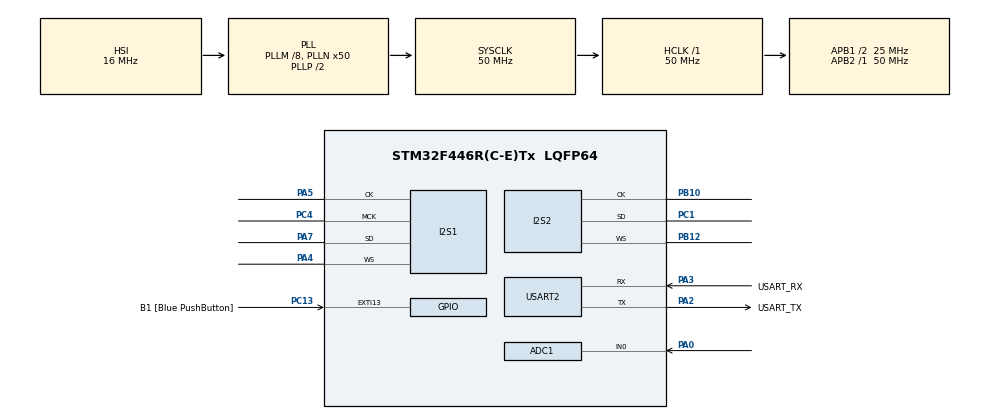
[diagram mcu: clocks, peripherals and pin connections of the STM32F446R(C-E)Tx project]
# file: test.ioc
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Mcu.Family=STM32F4
PH0-OSC_IN.Signal=RCC_OSC_IN
RCC.CortexFreq_Value=50000000
I2S1.ErrorAudioFreq=1.72 %
PB10.Mode=Half_Duplex_Master
ADC1.ContinuousConvMode=DISABLE
PA14.GPIO_Label=TCK
Dma.SPI2_TX.1.PeriphInc=DMA_PINC_DISABLE
I2S1.Mode=I2S_MODE_MASTER_RX
PC13.GPIO_Label=B1 [Blue PushButton]
NVIC.DMA1_Stream4_IRQn=true\:0\:0\:false\:false\:true\:false\:true
I2S1.Instance=SPI$Index
RCC.SYSCLKSource=RCC_SYSCLKSOURCE_PLLCLK
ProjectManager.StackSize=0x400
Dma.SPI1_RX.0.Direction=DMA_PERIPH_TO_MEMORY
PA4.Mode=Half_Duplex_Master
I2S1.DataFormat=I2S_DATAFORMAT_24B
RCC.HCLKFreq_Value=50000000
ADC1.Resolution=ADC_RESOLUTION_10B
RCC.APB2TimFreq_Value=50000000
NVIC.DMA2_Stream0_IRQn=true\:0\:0\:false\:false\:true\:false\:true
RCC.AHBFreq_Value=50000000
PH0-OSC_IN.Mode=HSE-External-Oscillator
ADC1.Channel-0\#ChannelRegularConversion=ADC_CHANNEL_0
RCC.HSE_VALUE=8000000
Dma.SPI1_RX.0.PeriphInc=DMA_PINC_DISABLE
PC14-OSC32_IN.Mode=LSE-External-Oscillator
PA14.Mode=Serial_Wire
SH.ADCx_IN0.0=ADC1_IN0,IN0
I2S2.DataFormat=I2S_DATAFORMAT_24B
ADC1.SamplingTime-0\#ChannelRegularConversion=ADC_SAMPLETIME_3CYCLES
RCC.FLatency-AdvancedSettings=FLASH_LATENCY_1
Dma.SPI2_TX.1.FIFOMode=DMA_FIFOMODE_DISABLE
PH1-OSC_OUT.Mode=HSE-External-Oscillator
Mcu.Package=LQFP64
PB12.Mode=Half_Duplex_Master
Dma.SPI2_TX.1.Mode=DMA_CIRCULAR
USART2.VirtualMode=VM_ASYNC
PA2.GPIO_Label=USART_TX
Dma.SPI2_TX.1.Instance=DMA1_Stream4
Dma.Request1=SPI2_TX
RCC.APB1TimFreq_Value=50000000
Dma.Request0=SPI1_RX
PC4.Mode=Master_Clock_Activated
PA3.Signal=USART2_RX
PA5.Mode=Half_Duplex_Master
PB3.GPIO_Label=SWO
PC15-OSC32_OUT.Mode=LSE-External-Oscillator
Dma.SPI2_TX.1.MemInc=DMA_MINC_ENABLE
I2S2.AudioFreq=I2S_AUDIOFREQ_48K
ADC1.Rank-0\#ChannelRegularConversion=1
PA7.Mode=Half_Duplex_Master
I2S2.Instance=SPI$Index
PC13.Signal=GPXTI13
PC4.Signal=I2S1_MCK
I2S1.AudioFreq=I2S_AUDIOFREQ_48K
Dma.SPI1_RX.0.Mode=DMA_CIRCULAR
RCC.APB1CLKDivider=RCC_HCLK_DIV2
PC14-OSC32_IN.Signal=RCC_OSC32_IN
PA0-WKUP.Signal=ADCx_IN0
Dma.SPI1_RX.0.FIFOMode=DMA_FIFOMODE_DISABLE
PA13.Signal=SYS_JTMS-SWDIO
PA3.Mode=Asynchronous
ProjectManager.TargetToolchain=STM32CubeIDE
I2S1.VirtualMode=I2S_MODE_MASTER
I2S2.VirtualMode=I2S_MODE_MASTER
RCC.USBFreq_Value=50000000
PC15-OSC32_OUT.Signal=RCC_OSC32_OUT
PB10.Signal=I2S2_CK
PA5.Signal=I2S1_CK
board=NUCLEO-F446RE
Dma.SPI2_TX.1.Direction=DMA_MEMORY_TO_PERIPH
RCC.VCOOutputFreq_Value=100000000
RCC.APB2Freq_Value=50000000
Dma.SPI2_TX.1.PeriphDataAlignment=DMA_PDATAALIGN_WORD
Dma.SPI2_TX.1.Priority=DMA_PRIORITY_LOW
Dma.SPI1_RX.0.Instance=DMA2_Stream0
Dma.SPI1_RX.0.PeriphDataAlignment=DMA_PDATAALIGN_WORD
PH1-OSC_OUT.Signal=RCC_OSC_OUT
Dma.SPI1_RX.0.MemDataAlignment=DMA_MDATAALIGN_WORD
I2S1.FullDuplexMode=I2S_FULLDUPLEXMODE_DISABLE
PA13.Mode=Serial_Wire
Mcu.Name=STM32F446R(C-E)Tx
Dma.SPI1_RX.0.MemInc=DMA_MINC_ENABLE
PA2.Signal=USART2_TX
PA13.GPIO_Label=TMS
I2S2.FullDuplexMode=I2S_FULLDUPLEXMODE_DISABLE
RCC.48MHZClocksFreq_Value=84000000
PB3.Signal=SYS_JTDO-SWO
PA4.Signal=I2S1_WS
RCC.SYSCLKFreq_VALUE=50000000
ADC1.master=1
I2S2.ErrorAudioFreq=1.72 %
PC13.GPIO_ModeDefaultEXTI=GPIO_MODE_IT_FALLING
PA14.Signal=SYS_JTCK-SWCLK
ProjectManager.HeapSize=0x200
Dma.SPI1_RX.0.Priority=DMA_PRIORITY_LOW
RCC.HSI_VALUE=16000000
NVIC.PriorityGroup=NVIC_PRIORITYGROUP_0
ADC1.NbrOfConversionFlag=1
RCC.PLLM=8
RCC.PLLN=50
PA2.Mode=Asynchronous
I2S1.RealAudioFreq=48.828 KHz
RCC.APB1Freq_Value=25000000
I2S2.RealAudioFreq=48.828 KHz
Dma.SPI2_TX.1.MemDataAlignment=DMA_MDATAALIGN_WORD
RCC.PLLI2SN=50
PC1.Signal=I2S2_SD
PB12.Signal=I2S2_WS
PC1.Mode=Half_Duplex_Master
PA3.GPIO_Label=USART_RX
RCC.PLLI2SM=8
PA7.Signal=I2S1_SD

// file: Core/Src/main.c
/* USER CODE BEGIN Header */
/**
  ******************************************************************************
  * @file           : main.c
  * @brief          : Main program body
  ******************************************************************************
  * @attention
  *
  * <h2><center>&copy; Copyright (c) 2021 STMicroelectronics.
  * All rights reserved.</center></h2>
  *
  * This software component is licensed by ST under BSD 3-Clause license,
  * the "License"; You may not use this file except in compliance with the
  * License. You may obtain a copy of the License at:
  *                        opensource.org/licenses/BSD-3-Clause
  *
  ******************************************************************************
  */
/* USER CODE END Header */
#include "main.h"

ADC_HandleTypeDef hadc1;

I2S_HandleTypeDef hi2s1;
I2S_HandleTypeDef hi2s2;
DMA_HandleTypeDef hdma_spi1_rx;
DMA_HandleTypeDef hdma_spi2_tx;

UART_HandleTypeDef huart2;

void SystemClock_Config(void);
static void MX_GPIO_Init(void);
static void MX_DMA_Init(void);
static void MX_USART2_UART_Init(void);
static void MX_I2S1_Init(void);
static void MX_I2S2_Init(void);
static void MX_ADC1_Init(void);
/* USER CODE BEGIN PFP */
uint16_t rxBuf[8];
uint16_t txBuf[8];
//volatile int v=1;
/* USER CODE END PFP */

int main(void)
{

  /* MCU Configuration--------------------------------------------------------*/

  /* Reset of all peripherals, Initializes the Flash interface and the Systick. */
  HAL_Init();

  /* Configure the system clock */
  SystemClock_Config();

  /* Initialize all configured peripherals */
  MX_GPIO_Init();
  MX_DMA_Init();
  MX_USART2_UART_Init();
  MX_I2S1_Init();
  MX_I2S2_Init();
  MX_ADC1_Init();
  HAL_I2S_Receive_DMA(&hi2s1, rxBuf, 4);
  HAL_I2S_Transmit_DMA(&hi2s2, txBuf, 4);

  /* Infinite loop */
  while (1)
  {

  }
}
void HAL_I2S_RxHalfCpltCallback(I2S_HandleTypeDef *hi2s1)
{
	  int left=(rxBuf[0]<<16 | rxBuf[1]);
	  int right=(rxBuf[2]<<16 | rxBuf[3]);
	  txBuf[0]=(left>>16)&0xFFFF;
	  txBuf[1]=left&0xFFFF;
	  txBuf[2]=(right>>16)&0xFFFF;
	  txBuf[3]=right&0xFFFF;
}
void HAL_I2S_RxCpltCallback(I2S_HandleTypeDef *hi2s1)
{
	  int left=(rxBuf[4]<<16 | rxBuf[5]);
	  int right=(rxBuf[6]<<16 | rxBuf[7]);
	  txBuf[4]=(left>>16)&0xFFFF;
	  txBuf[5]=left&0xFFFF;
	  txBuf[6]=(right>>16)&0xFFFF;
	  txBuf[7]=right&0xFFFF;
}
void SystemClock_Config(void)
{
  RCC_OscInitTypeDef RCC_OscInitStruct = {0};
  RCC_ClkInitTypeDef RCC_ClkInitStruct = {0};
  RCC_PeriphCLKInitTypeDef PeriphClkInitStruct = {0};

  /** Configure the main internal regulator output voltage
  */
  __HAL_RCC_PWR_CLK_ENABLE();
  __HAL_PWR_VOLTAGESCALING_CONFIG(PWR_REGULATOR_VOLTAGE_SCALE3);
  /** Initializes the RCC Oscillators according to the specified parameters
  * in the RCC_OscInitTypeDef structure.
  */
  RCC_OscInitStruct.OscillatorType = RCC_OSCILLATORTYPE_HSI;
  RCC_OscInitStruct.HSIState = RCC_HSI_ON;
  RCC_OscInitStruct.HSICalibrationValue = RCC_HSICALIBRATION_DEFAULT;
  RCC_OscInitStruct.PLL.PLLState = RCC_PLL_ON;
  RCC_OscInitStruct.PLL.PLLSource = RCC_PLLSOURCE_HSI;
  RCC_OscInitStruct.PLL.PLLM = 8;
  RCC_OscInitStruct.PLL.PLLN = 50;
  RCC_OscInitStruct.PLL.PLLP = RCC_PLLP_DIV2;
  RCC_OscInitStruct.PLL.PLLQ = 2;
  RCC_OscInitStruct.PLL.PLLR = 2;
  if (HAL_RCC_OscConfig(&RCC_OscInitStruct) != HAL_OK)
  {
    Error_Handler();
  }
  /** Initializes the CPU, AHB and APB buses clocks
  */
  RCC_ClkInitStruct.ClockType = RCC_CLOCKTYPE_HCLK|RCC_CLOCKTYPE_SYSCLK
                              |RCC_CLOCKTYPE_PCLK1|RCC_CLOCKTYPE_PCLK2;
  RCC_ClkInitStruct.SYSCLKSource = RCC_SYSCLKSOURCE_PLLCLK;
  RCC_ClkInitStruct.AHBCLKDivider = RCC_SYSCLK_DIV1;
  RCC_ClkInitStruct.APB1CLKDivider = RCC_HCLK_DIV2;
  RCC_ClkInitStruct.APB2CLKDivider = RCC_HCLK_DIV1;

  if (HAL_RCC_ClockConfig(&RCC_ClkInitStruct, FLASH_LATENCY_1) != HAL_OK)
  {
    Error_Handler();
  }
  PeriphClkInitStruct.PeriphClockSelection = RCC_PERIPHCLK_I2S_APB1|RCC_PERIPHCLK_I2S_APB2;
  PeriphClkInitStruct.PLLI2S.PLLI2SN = 50;
  PeriphClkInitStruct.PLLI2S.PLLI2SP = RCC_PLLI2SP_DIV2;
  PeriphClkInitStruct.PLLI2S.PLLI2SM = 8;
  PeriphClkInitStruct.PLLI2S.PLLI2SR = 2;
  PeriphClkInitStruct.PLLI2S.PLLI2SQ = 2;
  PeriphClkInitStruct.PLLI2SDivQ = 1;
  PeriphClkInitStruct.I2sApb2ClockSelection = RCC_I2SAPB2CLKSOURCE_PLLI2S;
  PeriphClkInitStruct.I2sApb1ClockSelection = RCC_I2SAPB1CLKSOURCE_PLLI2S;
  if (HAL_RCCEx_PeriphCLKConfig(&PeriphClkInitStruct) != HAL_OK)
  {
    Error_Handler();
  }
}

static void MX_ADC1_Init(void)
{

  ADC_ChannelConfTypeDef sConfig = {0};

  /** Configure the global features of the ADC (Clock, Resolution, Data Alignment and number of conversion)
  */
  hadc1.Instance = ADC1;
  hadc1.Init.ClockPrescaler = ADC_CLOCK_SYNC_PCLK_DIV2;
  hadc1.Init.Resolution = ADC_RESOLUTION_10B;
  hadc1.Init.ScanConvMode = DISABLE;
  hadc1.Init.ContinuousConvMode = DISABLE;
  hadc1.Init.DiscontinuousConvMode = DISABLE;
  hadc1.Init.ExternalTrigConvEdge = ADC_EXTERNALTRIGCONVEDGE_NONE;
  hadc1.Init.ExternalTrigConv = ADC_SOFTWARE_START;
  hadc1.Init.DataAlign = ADC_DATAALIGN_RIGHT;
  hadc1.Init.NbrOfConversion = 1;
  hadc1.Init.DMAContinuousRequests = DISABLE;
  hadc1.Init.EOCSelection = ADC_EOC_SINGLE_CONV;
  if (HAL_ADC_Init(&hadc1) != HAL_OK)
  {
    Error_Handler();
  }
  /** Configure for the selected ADC regular channel its corresponding rank in the sequencer and its sample time.
  */
  sConfig.Channel = ADC_CHANNEL_0;
  sConfig.Rank = 1;
  sConfig.SamplingTime = ADC_SAMPLETIME_3CYCLES;
  if (HAL_ADC_ConfigChannel(&hadc1, &sConfig) != HAL_OK)
  {
    Error_Handler();
  }

}

static void MX_I2S1_Init(void)
{

  hi2s1.Instance = SPI1;
  hi2s1.Init.Mode = I2S_MODE_MASTER_RX;
  hi2s1.Init.Standard = I2S_STANDARD_PHILIPS;
  hi2s1.Init.DataFormat = I2S_DATAFORMAT_24B;
  hi2s1.Init.MCLKOutput = I2S_MCLKOUTPUT_ENABLE;
  hi2s1.Init.AudioFreq = I2S_AUDIOFREQ_48K;
  hi2s1.Init.CPOL = I2S_CPOL_LOW;
  hi2s1.Init.ClockSource = I2S_CLOCK_PLL;
  hi2s1.Init.FullDuplexMode = I2S_FULLDUPLEXMODE_DISABLE;
  if (HAL_I2S_Init(&hi2s1) != HAL_OK)
  {
    Error_Handler();
  }

}

static void MX_I2S2_Init(void)
{

  hi2s2.Instance = SPI2;
  hi2s2.Init.Mode = I2S_MODE_MASTER_TX;
  hi2s2.Init.Standard = I2S_STANDARD_PHILIPS;
  hi2s2.Init.DataFormat = I2S_DATAFORMAT_24B;
  hi2s2.Init.MCLKOutput = I2S_MCLKOUTPUT_DISABLE;
  hi2s2.Init.AudioFreq = I2S_AUDIOFREQ_48K;
  hi2s2.Init.CPOL = I2S_CPOL_LOW;
  hi2s2.Init.ClockSource = I2S_CLOCK_PLL;
  hi2s2.Init.FullDuplexMode = I2S_FULLDUPLEXMODE_DISABLE;
  if (HAL_I2S_Init(&hi2s2) != HAL_OK)
  {
    Error_Handler();
  }

}

static void MX_USART2_UART_Init(void)
{

  huart2.Instance = USART2;
  huart2.Init.BaudRate = 115200;
  huart2.Init.WordLength = UART_WORDLENGTH_8B;
  huart2.Init.StopBits = UART_STOPBITS_1;
  huart2.Init.Parity = UART_PARITY_NONE;
  huart2.Init.Mode = UART_MODE_TX_RX;
  huart2.Init.HwFlowCtl = UART_HWCONTROL_NONE;
  huart2.Init.OverSampling = UART_OVERSAMPLING_16;
  if (HAL_UART_Init(&huart2) != HAL_OK)
  {
    Error_Handler();
  }

}

static void MX_DMA_Init(void)
{

  /* DMA controller clock enable */
  __HAL_RCC_DMA2_CLK_ENABLE();
  __HAL_RCC_DMA1_CLK_ENABLE();

  /* DMA interrupt init */
  /* DMA1_Stream4_IRQn interrupt configuration */
  HAL_NVIC_SetPriority(DMA1_Stream4_IRQn, 0, 0);
  HAL_NVIC_EnableIRQ(DMA1_Stream4_IRQn);
  /* DMA2_Stream0_IRQn interrupt configuration */
  HAL_NVIC_SetPriority(DMA2_Stream0_IRQn, 0, 0);
  HAL_NVIC_EnableIRQ(DMA2_Stream0_IRQn);

}

static void MX_GPIO_Init(void)
{
  GPIO_InitTypeDef GPIO_InitStruct = {0};

  /* GPIO Ports Clock Enable */
  __HAL_RCC_GPIOC_CLK_ENABLE();
  __HAL_RCC_GPIOH_CLK_ENABLE();
  __HAL_RCC_GPIOA_CLK_ENABLE();
  __HAL_RCC_GPIOB_CLK_ENABLE();

  /*Configure GPIO pin : B1_Pin */
  GPIO_InitStruct.Pin = B1_Pin;
  GPIO_InitStruct.Mode = GPIO_MODE_IT_FALLING;
  GPIO_InitStruct.Pull = GPIO_NOPULL;
  HAL_GPIO_Init(B1_GPIO_Port, &GPIO_InitStruct);

}

void Error_Handler(void)
{
  __disable_irq();
  while (1)
  {
  }
}

/************************ (C) COPYRIGHT STMicroelectronics *****END OF FILE****/
